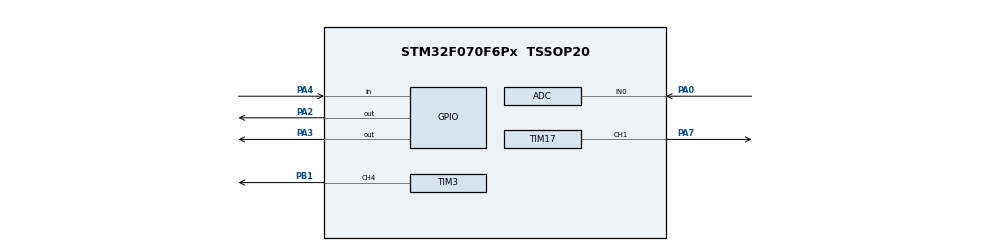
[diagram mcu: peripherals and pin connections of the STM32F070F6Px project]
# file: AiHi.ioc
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Mcu.Family=STM32F0
Mcu.Name=STM32F070F6Px
Mcu.Package=TSSOP20
NVIC.RTC_IRQn=true\:0\:0\:false\:false\:true\:true\:true
PA0.Mode=IN0
PA0.Signal=ADC_IN0
PA13.Mode=Serial_Wire
PA13.Signal=SYS_SWDIO
PA14.Mode=Serial_Wire
PA14.Signal=SYS_SWCLK
PA2.Signal=GPIO_Output
PA3.Signal=GPIO_Output
PA4.Signal=GPIO_Input
PA5.Signal=ADC_IN5
PA7.Signal=S_TIM17_CH1
PB1.Signal=S_TIM3_CH4
ProjectManager.HeapSize=0x200
ProjectManager.StackSize=0x400
ProjectManager.TargetToolchain=STM32CubeIDE
RCC.AHBFreq_Value=48000000
RCC.APB1Freq_Value=48000000
RCC.APB1TimFreq_Value=48000000
RCC.HCLKFreq_Value=48000000
RCC.PLLMUL=RCC_PLL_MUL6
RCC.SYSCLKFreq_VALUE=48000000
RCC.SYSCLKSource=RCC_SYSCLKSOURCE_PLLCLK
RTC.Alarm=RTC_ALARM_A
RTC.AlarmMaskDateWeekDay=RTC_ALARMMASK_DATEWEEKDAY
RTC.AlarmMaskHours=RTC_ALARMMASK_HOURS
RTC.AlarmMaskMinutes=RTC_ALARMMASK_MINUTES
RTC.AlarmMaskSeconds=RTC_ALARMMASK_SECONDS
RTC.Seconds_A=0
SH.S_TIM17_CH1.0=TIM17_CH1,PWM Generation1 CH1
SH.S_TIM3_CH4.0=TIM3_CH4,PWM Generation4 CH4
TIM17.Channel=TIM_CHANNEL_1
TIM17.Period=48000
TIM17.Prescaler=1000
TIM17.Pulse=48000
TIM3.Channel-PWM\ Generation4\ CH4=TIM_CHANNEL_4
TIM3.Period=4800
TIM3.Pulse-PWM\ Generation4\ CH4=2400
VP_RTC_VS_RTC_Activate.Mode=RTC_Enabled
VP_RTC_VS_RTC_Alarm_A_Intern.Mode=Alarm A
VP_RTC_VS_RTC_Calendar.Mode=RTC_Calendar
VP_SYS_VS_PINREMAP.Mode=PINREMAP
VP_TIM17_VS_ClockSourceINT.Mode=Enable_Timer
VP_TIM3_VS_ClockSourceINT.Mode=Internal
board=custom

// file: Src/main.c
/* USER CODE BEGIN Header */
/**
  ******************************************************************************
  * @file           : main.c
  * @brief          : Main program body
  ******************************************************************************
  * @attention
  *
  * <h2><center>&copy; Copyright (c) 2020 STMicroelectronics.
  * All rights reserved.</center></h2>
  *
  * This software component is licensed by ST under Ultimate Liberty license
  * SLA0044, the "License"; You may not use this file except in compliance with
  * the License. You may obtain a copy of the License at:
  *                             www.st.com/SLA0044
  *
  ******************************************************************************
  */
/* USER CODE END Header */

#include "main.h"
#include "adc.h"
#include "rtc.h"
#include "tim.h"
#include "gpio.h"

/* USER CODE BEGIN Includes */
#include "myPid.h"
/* USER CODE END Includes */

/* USER CODE BEGIN PV */
volatile float TestTemp = 0;

/* USER CODE END PV */

void SystemClock_Config(void);

int main(void)
{

  /* MCU Configuration--------------------------------------------------------*/

  /* Reset of all peripherals, Initializes the Flash interface and the Systick. */
  HAL_Init();

  /* Configure the system clock */
  SystemClock_Config();

  /* Initialize all configured peripherals */
  MX_GPIO_Init();
  MX_ADC_Init();
  MX_TIM3_Init();
  MX_TIM17_Init();
  MX_RTC_Init();
  /* USER CODE BEGIN 2 */
  TIM_StartGeneration();
  TIM_SetGenFreq(1000);
  /* USER CODE END 2 */

  /* Infinite loop */
  while (1)
  {

    /* USER CODE BEGIN 3 */
	  //GPIO_Blink();
	  ADC_StartMeas();
	  TestTemp = NTC_read(1);
  }
  /* USER CODE END 3 */
}

void SystemClock_Config(void)
{
  LL_FLASH_SetLatency(LL_FLASH_LATENCY_1);

  if(LL_FLASH_GetLatency() != LL_FLASH_LATENCY_1)
  {
  Error_Handler();
  }
  LL_RCC_HSI_Enable();

   /* Wait till HSI is ready */
  while(LL_RCC_HSI_IsReady() != 1)
  {

  }
  LL_RCC_HSI_SetCalibTrimming(16);
  LL_RCC_HSI14_Enable();

   /* Wait till HSI14 is ready */
  while(LL_RCC_HSI14_IsReady() != 1)
  {

  }
  LL_RCC_HSI14_SetCalibTrimming(16);
  LL_RCC_LSI_Enable();

   /* Wait till LSI is ready */
  while(LL_RCC_LSI_IsReady() != 1)
  {

  }
  LL_PWR_EnableBkUpAccess();
  LL_RCC_ForceBackupDomainReset();
  LL_RCC_ReleaseBackupDomainReset();
  LL_RCC_SetRTCClockSource(LL_RCC_RTC_CLKSOURCE_LSI);
  LL_RCC_EnableRTC();
  LL_RCC_PLL_ConfigDomain_SYS(LL_RCC_PLLSOURCE_HSI, LL_RCC_PLL_MUL_6, LL_RCC_PREDIV_DIV_1);
  LL_RCC_PLL_Enable();

   /* Wait till PLL is ready */
  while(LL_RCC_PLL_IsReady() != 1)
  {

  }
  LL_RCC_SetAHBPrescaler(LL_RCC_SYSCLK_DIV_1);
  LL_RCC_SetAPB1Prescaler(LL_RCC_APB1_DIV_1);
  LL_RCC_SetSysClkSource(LL_RCC_SYS_CLKSOURCE_PLL);

   /* Wait till System clock is ready */
  while(LL_RCC_GetSysClkSource() != LL_RCC_SYS_CLKSOURCE_STATUS_PLL)
  {

  }
  LL_SetSystemCoreClock(48000000);

   /* Update the time base */
  if (HAL_InitTick (TICK_INT_PRIORITY) != HAL_OK)
  {
    Error_Handler();
  };
  LL_RCC_HSI14_EnableADCControl();
}

void Error_Handler(void)
{
}

/************************ (C) COPYRIGHT STMicroelectronics *****END OF FILE****/
